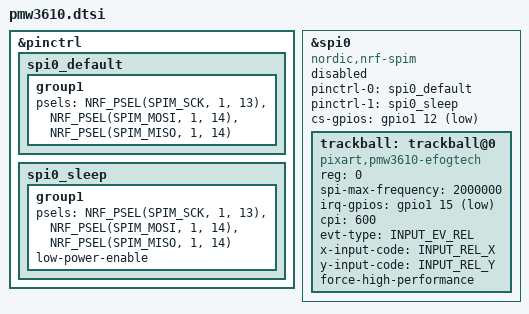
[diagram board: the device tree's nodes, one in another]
/* 
    For the *peripheral* side that has SPI pointing device with it. Not even dongle.overlay should have this.
    What's here: pinctrl & trackball input device node (SPI) for right & dongle side.
*/

&pinctrl {
    spi0_default: spi0_default {
        group1 {
            psels = <NRF_PSEL(SPIM_SCK,  1, 13)>, // SCLK P1.13
                    <NRF_PSEL(SPIM_MOSI, 1, 14)>, // SDIO P1.14
                    <NRF_PSEL(SPIM_MISO, 1, 14)>; // SDIO P1.14
        };
    };

    spi0_sleep: spi0_sleep {
        group1 {
            psels = <NRF_PSEL(SPIM_SCK,  1, 13)>, // SCLK P1.13
                    <NRF_PSEL(SPIM_MOSI, 1, 14)>, // SDIO P1.14
                    <NRF_PSEL(SPIM_MISO, 1, 14)>; // SDIO P1.14
            low-power-enable;
        };
    };
};

#include <zephyr/dt-bindings/input/input-event-codes.h>

&spi0 { // input device node (SPI)
    status = "disabled";
    compatible = "nordic,nrf-spim";
    pinctrl-0 = <&spi0_default>;
    pinctrl-1 = <&spi0_sleep>;
    pinctrl-names = "default", "sleep";
    cs-gpios = <&gpio1 12 GPIO_ACTIVE_LOW>; // NCS P1.12

    trackball: trackball@0 {
        status = "okay";
        compatible = "pixart,pmw3610-efogtech";
        reg = <0>; // refers to the first SPI slave device
        spi-max-frequency = <2000000>;
        irq-gpios = <&gpio1 15 (GPIO_ACTIVE_LOW | GPIO_PULL_UP)>; // MOT P1.15
        cpi = <600>;
        evt-type = <INPUT_EV_REL>;
        x-input-code = <INPUT_REL_X>;
        y-input-code = <INPUT_REL_Y>;

        // force-awake will cause warping and cursor jumping. Don't recommend now.
        force-high-performance;
    };
};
